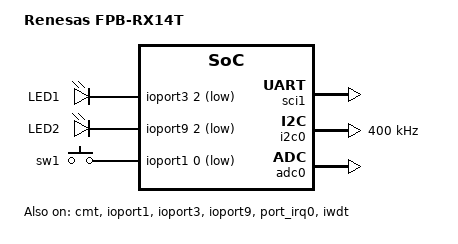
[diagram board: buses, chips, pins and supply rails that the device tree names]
/*
 * Copyright (c) 2026 Renesas Electronics Corporation
 *
 * SPDX-License-Identifier: Apache-2.0
 */

/dts-v1/;

#include <renesas/r5f514t5amfm.dtsi>
#include <zephyr/dt-bindings/gpio/gpio.h>
#include "fpb_rx14t-pinctrl.dtsi"
#include <zephyr/dt-bindings/adc/adc.h>
#include <zephyr/dt-bindings/input/input-event-codes.h>

/ {
	model = "Renesas FPB-RX14T";
	compatible = "renesas,fpb_rx14t";

	chosen {
		zephyr,sram = &sram0;
		zephyr,flash = &code_flash;
		zephyr,flash-controller = &flash;
		zephyr,console = &uart1;
		zephyr,shell-uart = &uart1;
	};

	leds {
		compatible = "gpio-leds";

		led1: led1 {
			gpios = <&ioport3 2 GPIO_ACTIVE_LOW>;
			label = "LED1";
		};

		led2: led2 {
			gpios = <&ioport9 2 GPIO_ACTIVE_LOW>;
			label = "LED2";
		};
	};

	buttons {
		compatible = "gpio-keys";

		sw1: button {
			label = "sw1";
			gpios = <&ioport1 0 (GPIO_PULL_UP | GPIO_ACTIVE_LOW)>;
			zephyr,code = <INPUT_KEY_0>;
		};
	};

	aliases {
		led0 = &led1;
		led1 = &led2;
		sw0 = &sw1;
		watchdog0 = &iwdt;
	};
};

&cmt {
	clock-frequency = <4000000>;
	status = "okay";
};

&pclkblock {
	clocks = <&hoco>;
};

&clkout {
	clocks = <&hoco>;
};

&ioport1 {
	status = "okay";
};

&iwdtlsclk {
	status = "okay";
};

&ioport3 {
	status = "okay";
};

&ioport9 {
	status = "okay";
};

&port_irq0 {
	status = "okay";
};

&sci1 {
	pinctrl-0 = <&sci1_default>;
	pinctrl-names = "default";
	status = "okay";

	uart1: uart {
		current-speed = <115200>;
		status = "okay";
	};
};

&data_flash {
	partitions {
		compatible = "fixed-partitions";
		#address-cells = <1>;
		#size-cells = <1>;

		storage_partition: partition@0 {
			label = "storage";
			reg = <0x0 DT_SIZE_K(4)>;
		};
	};
};

&i2c0 {
	pinctrl-0 = <&i2c0_default>;
	pinctrl-names = "default";
	clock-frequency = <DT_FREQ_K(400)>;
	status = "okay";
};

&adc0 {
	pinctrl-0 = <&adc0_default>;
	pinctrl-names = "default";
	status = "okay";
};

&iwdt {
	window-start = <0x3000>;
	window-end = <0x0300>;
	status = "okay";
};
